# PAT0_CFG_TABLE register map
Vendor: Texas Instruments
Peripheral module from a debugger description file (folder J7ES).
Registers are 32-bit, read-write, reset 0x0 unless marked. A register's access mark holds for its fields unless they carry their own. Offsets are as the file gives them; lines under a group give offsets from that group; [hi:lo] are bit positions; {n}, {i} and the like mark numbered series; 'fields as' and 'values as' point back to an identical list; <NAME> marks a mode.

## PAT0_CFG_TABLE
0x00 PAT_BASE_REG_L_j_k — The Base Low Address bits 43 to 12 for Page. This register must be written as a full 32-bit word. Offset = 0h + (j * 1000h) + (k * 8h); where j = 0h to 3Fh, k = 0h to FFh for PAT0, PAT1, and PAT2 Offset = 0h + (j * 1000h) + (k * 8h); where j = 0h to 7h, k = 0h to FFh for PAT3 and PAT4
  [31:0] BASE_L — Translated Base Address bits 43 to 12 for Page. Always minimum 4KB aligned.
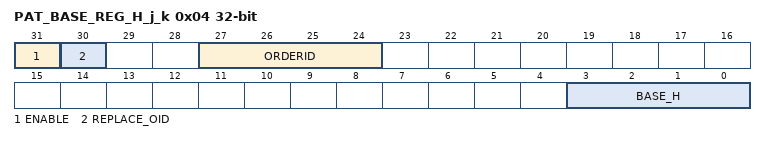
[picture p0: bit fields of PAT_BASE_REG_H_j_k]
0x04 PAT_BASE_REG_H_j_k access per field — The Base High Address bits 47 to 44 for Page. This register must be written as a full 32-bit word. Offset = 4h + (j * 1000h) + (k * 8h); where j = 0h to 3Fh, k = 0h to FFh for PAT0, PAT1, and PAT2 Offset = 4h + (j * 1000h) + (k * 8h); where j = 0h to 7h, k = 0h to FFh for PAT3 and PAT4
  [31] ENABLE rw — Translation Enable for Page. 0 = disabled. 1 = enabled.
  [30] REPLACE_OID ro — OrderID replacement Enable for Page. It will be ignored if the global replace orderid is disabled. 0 = use input orderid. 1 = force replacement to orderid in page.
  [27:24] ORDERID ro — Translated orderid to use with translation address.
  [3:0] BASE_H rw — Translated Base Address bits 47 to 44 for Page
